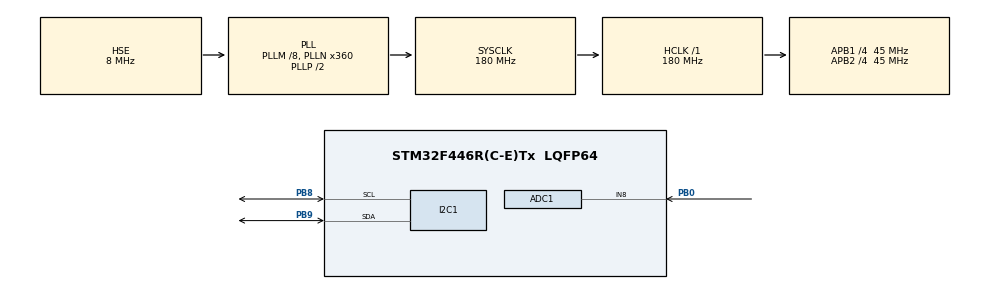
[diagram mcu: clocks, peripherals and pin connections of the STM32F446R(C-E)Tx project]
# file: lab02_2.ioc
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ADC1.Channel-12\#ChannelRegularConversion=ADC_CHANNEL_8
ADC1.ExternalTrigConv=ADC_EXTERNALTRIGCONV_T3_TRGO
ADC1.NbrOfConversionFlag=1
ADC1.Rank-12\#ChannelRegularConversion=1
ADC1.SamplingTime-12\#ChannelRegularConversion=ADC_SAMPLETIME_3CYCLES
ADC1.master=1
I2C1.I2C_Mode=I2C_Fast
Mcu.Family=STM32F4
Mcu.Name=STM32F446R(C-E)Tx
Mcu.Package=LQFP64
NVIC.ADC_IRQn=true\:0\:0\:false\:false\:true\:true\:true\:true
NVIC.PriorityGroup=NVIC_PRIORITYGROUP_4
PA13.Mode=Serial_Wire
PA13.Signal=SYS_JTMS-SWDIO
PA14.Mode=Serial_Wire
PA14.Signal=SYS_JTCK-SWCLK
PB0.Signal=ADCx_IN8
PB8.Mode=I2C
PB8.Signal=I2C1_SCL
PB9.Mode=I2C
PB9.Signal=I2C1_SDA
PH0-OSC_IN.Mode=HSE-External-Oscillator
PH0-OSC_IN.Signal=RCC_OSC_IN
PH1-OSC_OUT.Mode=HSE-External-Oscillator
PH1-OSC_OUT.Signal=RCC_OSC_OUT
ProjectManager.HeapSize=0x200
ProjectManager.StackSize=0x400
ProjectManager.TargetToolchain=STM32CubeIDE
RCC.AHBFreq_Value=180000000
RCC.APB1CLKDivider=RCC_HCLK_DIV4
RCC.APB1Freq_Value=45000000
RCC.APB1TimFreq_Value=90000000
RCC.APB2CLKDivider=RCC_HCLK_DIV4
RCC.APB2Freq_Value=45000000
RCC.APB2TimFreq_Value=90000000
RCC.CortexFreq_Value=180000000
RCC.HCLKFreq_Value=180000000
RCC.HSE_VALUE=8000000
RCC.PLLM=8
RCC.PLLN=360
RCC.PLLSourceVirtual=RCC_PLLSOURCE_HSE
RCC.SYSCLKFreq_VALUE=180000000
RCC.SYSCLKSource=RCC_SYSCLKSOURCE_PLLCLK
RCC.USBFreq_Value=180000000
RCC.VCOOutputFreq_Value=360000000
SH.ADCx_IN8.0=ADC1_IN8,IN8
TIM3.AutoReloadPreload=TIM_AUTORELOAD_PRELOAD_ENABLE
TIM3.Period=20-1
TIM3.Prescaler=90-1
TIM3.TIM_MasterOutputTrigger=TIM_TRGO_UPDATE
VP_TIM3_VS_ClockSourceINT.Mode=Internal
board=custom

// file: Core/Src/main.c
/* USER CODE BEGIN Header */
/**
  ******************************************************************************
  * @file           : main.c
  * @brief          : Main program body
  ******************************************************************************
  * @attention
  *
  * Copyright (c) 2026 STMicroelectronics.
  * All rights reserved.
  *
  * This software is licensed under terms that can be found in the LICENSE file
  * in the root directory of this software component.
  * If no LICENSE file comes with this software, it is provided AS-IS.
  *
  ******************************************************************************
  */
/* USER CODE END Header */
#include "main.h"

/* USER CODE BEGIN Includes */
#include <stdio.h>
#include <string.h>
#include "ssd1306.h"
/* USER CODE END Includes */

ADC_HandleTypeDef hadc1;

I2C_HandleTypeDef hi2c1;

TIM_HandleTypeDef htim3;

/* USER CODE BEGIN PV */
uint16_t data[1000];
int i=0;
int refVoltage = 2048;
/* USER CODE END PV */

void SystemClock_Config(void);
static void MX_GPIO_Init(void);
static void MX_ADC1_Init(void);
static void MX_I2C1_Init(void);
static void MX_TIM3_Init(void);

/* USER CODE BEGIN 0 */
void HAL_ADC_ConvCpltCallback(ADC_HandleTypeDef *hadc){
	if(hadc==&hadc1){
		data[i]=HAL_ADC_GetValue(hadc);
		i = (i+1)%1000;
		HAL_ADC_Start_IT(hadc);
	}
}

/* USER CODE END 0 */

int main(void)
{

  /* USER CODE BEGIN 1 */
  int start;
  /* USER CODE END 1 */

  /* MCU Configuration--------------------------------------------------------*/

  /* Reset of all peripherals, Initializes the Flash interface and the Systick. */
  HAL_Init();

  /* Configure the system clock */
  SystemClock_Config();

  /* Initialize all configured peripherals */
  MX_GPIO_Init();
  MX_ADC1_Init();
  MX_I2C1_Init();
  MX_TIM3_Init();
  /* USER CODE BEGIN 2 */
  HAL_ADC_Start_IT(&hadc1);
  HAL_TIM_Base_Start(&htim3);
  ssd1306_Init();
  /* USER CODE END 2 */

  /* Infinite loop */
  /* USER CODE BEGIN WHILE */
  while (1)
  {
	  int i;
	  //Show wave pattern on screen
	  for(start=0;start<800;start++){
		  //Track waveform at rising moment
		  if(data[start]>refVoltage)
			  break;
	  }
	  ssd1306_Fill(Black);
	  if(start>=800){
		  // Error tracking
		  ssd1306_SetCursor(0,0);
		  ssd1306_WriteString("Error Tracking",Font_7x10,White);
		  ssd1306_UpdateScreen();
		  HAL_Delay(100);
		  continue;
	  }
	  // Draw waveform
	  for(i=0;i<127;i++){
		  ssd1306_Line(i,31-(data[start]>>7),i,31-(data[start+1]>>7),White);
		  start++;
	  }
	  ssd1306_UpdateScreen();
	  HAL_Delay(100);
    /* USER CODE END WHILE */

  }
}

void SystemClock_Config(void)
{
  RCC_OscInitTypeDef RCC_OscInitStruct = {0};
  RCC_ClkInitTypeDef RCC_ClkInitStruct = {0};

  /** Configure the main internal regulator output voltage
  */
  __HAL_RCC_PWR_CLK_ENABLE();
  __HAL_PWR_VOLTAGESCALING_CONFIG(PWR_REGULATOR_VOLTAGE_SCALE1);

  /** Initializes the RCC Oscillators according to the specified parameters
  * in the RCC_OscInitTypeDef structure.
  */
  RCC_OscInitStruct.OscillatorType = RCC_OSCILLATORTYPE_HSE;
  RCC_OscInitStruct.HSEState = RCC_HSE_ON;
  RCC_OscInitStruct.PLL.PLLState = RCC_PLL_ON;
  RCC_OscInitStruct.PLL.PLLSource = RCC_PLLSOURCE_HSE;
  RCC_OscInitStruct.PLL.PLLM = 8;
  RCC_OscInitStruct.PLL.PLLN = 360;
  RCC_OscInitStruct.PLL.PLLP = RCC_PLLP_DIV2;
  RCC_OscInitStruct.PLL.PLLQ = 2;
  RCC_OscInitStruct.PLL.PLLR = 2;
  if (HAL_RCC_OscConfig(&RCC_OscInitStruct) != HAL_OK)
  {
    Error_Handler();
  }

  /** Activate the Over-Drive mode
  */
  if (HAL_PWREx_EnableOverDrive() != HAL_OK)
  {
    Error_Handler();
  }

  /** Initializes the CPU, AHB and APB buses clocks
  */
  RCC_ClkInitStruct.ClockType = RCC_CLOCKTYPE_HCLK|RCC_CLOCKTYPE_SYSCLK
                              |RCC_CLOCKTYPE_PCLK1|RCC_CLOCKTYPE_PCLK2;
  RCC_ClkInitStruct.SYSCLKSource = RCC_SYSCLKSOURCE_PLLCLK;
  RCC_ClkInitStruct.AHBCLKDivider = RCC_SYSCLK_DIV1;
  RCC_ClkInitStruct.APB1CLKDivider = RCC_HCLK_DIV4;
  RCC_ClkInitStruct.APB2CLKDivider = RCC_HCLK_DIV4;

  if (HAL_RCC_ClockConfig(&RCC_ClkInitStruct, FLASH_LATENCY_5) != HAL_OK)
  {
    Error_Handler();
  }
}

static void MX_ADC1_Init(void)
{

  ADC_ChannelConfTypeDef sConfig = {0};

  /** Configure the global features of the ADC (Clock, Resolution, Data Alignment and number of conversion)
  */
  hadc1.Instance = ADC1;
  hadc1.Init.ClockPrescaler = ADC_CLOCK_SYNC_PCLK_DIV2;
  hadc1.Init.Resolution = ADC_RESOLUTION_12B;
  hadc1.Init.ScanConvMode = DISABLE;
  hadc1.Init.ContinuousConvMode = DISABLE;
  hadc1.Init.DiscontinuousConvMode = DISABLE;
  hadc1.Init.ExternalTrigConvEdge = ADC_EXTERNALTRIGCONVEDGE_RISING;
  hadc1.Init.ExternalTrigConv = ADC_EXTERNALTRIGCONV_T3_TRGO;
  hadc1.Init.DataAlign = ADC_DATAALIGN_RIGHT;
  hadc1.Init.NbrOfConversion = 1;
  hadc1.Init.DMAContinuousRequests = DISABLE;
  hadc1.Init.EOCSelection = ADC_EOC_SINGLE_CONV;
  if (HAL_ADC_Init(&hadc1) != HAL_OK)
  {
    Error_Handler();
  }

  /** Configure for the selected ADC regular channel its corresponding rank in the sequencer and its sample time.
  */
  sConfig.Channel = ADC_CHANNEL_8;
  sConfig.Rank = 1;
  sConfig.SamplingTime = ADC_SAMPLETIME_3CYCLES;
  if (HAL_ADC_ConfigChannel(&hadc1, &sConfig) != HAL_OK)
  {
    Error_Handler();
  }

}

static void MX_I2C1_Init(void)
{

  hi2c1.Instance = I2C1;
  hi2c1.Init.ClockSpeed = 400000;
  hi2c1.Init.DutyCycle = I2C_DUTYCYCLE_2;
  hi2c1.Init.OwnAddress1 = 0;
  hi2c1.Init.AddressingMode = I2C_ADDRESSINGMODE_7BIT;
  hi2c1.Init.DualAddressMode = I2C_DUALADDRESS_DISABLE;
  hi2c1.Init.OwnAddress2 = 0;
  hi2c1.Init.GeneralCallMode = I2C_GENERALCALL_DISABLE;
  hi2c1.Init.NoStretchMode = I2C_NOSTRETCH_DISABLE;
  if (HAL_I2C_Init(&hi2c1) != HAL_OK)
  {
    Error_Handler();
  }

}

static void MX_TIM3_Init(void)
{

  TIM_ClockConfigTypeDef sClockSourceConfig = {0};
  TIM_MasterConfigTypeDef sMasterConfig = {0};

  htim3.Instance = TIM3;
  htim3.Init.Prescaler = 90-1;
  htim3.Init.CounterMode = TIM_COUNTERMODE_UP;
  htim3.Init.Period = 20-1;
  htim3.Init.ClockDivision = TIM_CLOCKDIVISION_DIV1;
  htim3.Init.AutoReloadPreload = TIM_AUTORELOAD_PRELOAD_ENABLE;
  if (HAL_TIM_Base_Init(&htim3) != HAL_OK)
  {
    Error_Handler();
  }
  sClockSourceConfig.ClockSource = TIM_CLOCKSOURCE_INTERNAL;
  if (HAL_TIM_ConfigClockSource(&htim3, &sClockSourceConfig) != HAL_OK)
  {
    Error_Handler();
  }
  sMasterConfig.MasterOutputTrigger = TIM_TRGO_UPDATE;
  sMasterConfig.MasterSlaveMode = TIM_MASTERSLAVEMODE_DISABLE;
  if (HAL_TIMEx_MasterConfigSynchronization(&htim3, &sMasterConfig) != HAL_OK)
  {
    Error_Handler();
  }

}

static void MX_GPIO_Init(void)
{

  /* GPIO Ports Clock Enable */
  __HAL_RCC_GPIOH_CLK_ENABLE();
  __HAL_RCC_GPIOB_CLK_ENABLE();
  __HAL_RCC_GPIOA_CLK_ENABLE();

}

void Error_Handler(void)
{
  __disable_irq();
  while (1)
  {
  }
}
